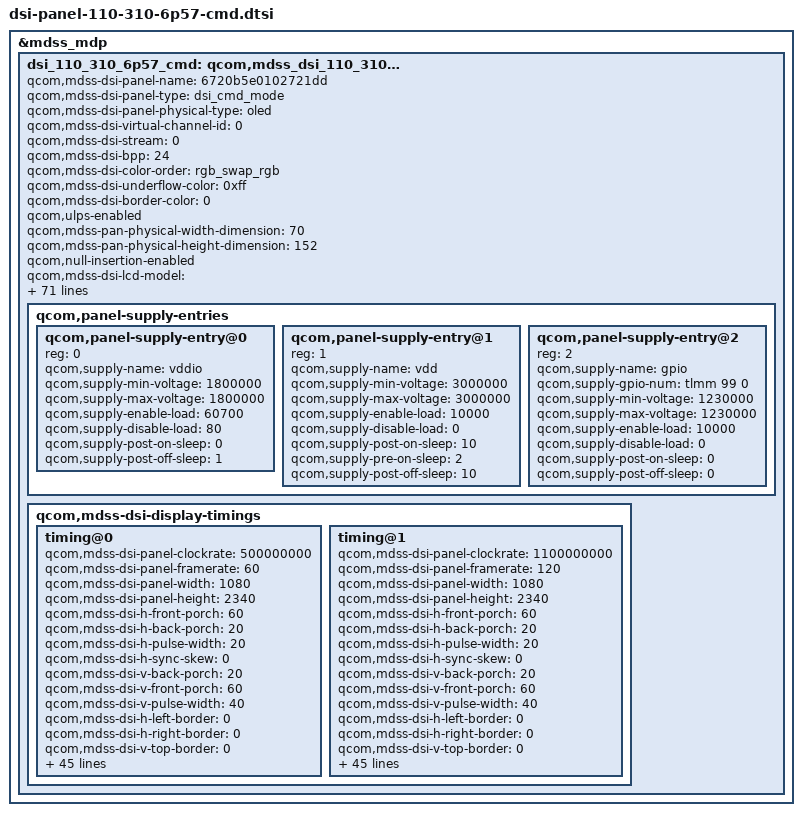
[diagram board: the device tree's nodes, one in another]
&mdss_mdp {
	dsi_110_310_6p57_cmd: qcom,mdss_dsi_110_310_6p57_cmd {
		qcom,mdss-dsi-panel-name = "6720b5e0102721dd";
		qcom,mdss-dsi-panel-type = "dsi_cmd_mode";
		qcom,mdss-dsi-panel-physical-type = "oled";
		qcom,mdss-dsi-virtual-channel-id = <0>;
		qcom,mdss-dsi-stream = <0>;
		qcom,mdss-dsi-bpp = <24>;
		qcom,mdss-dsi-color-order = "rgb_swap_rgb";
		qcom,mdss-dsi-underflow-color = <0xff>;
		qcom,mdss-dsi-border-color = <0>;
		qcom,ulps-enabled;
		qcom,mdss-pan-physical-width-dimension = <70>;
		qcom,mdss-pan-physical-height-dimension = <152>;
		qcom,null-insertion-enabled;
		qcom,mdss-dsi-lcd-model = "110_310 6p57 1080 x 2340";
		qcom,bl-dsc-cmd-state = "dsi_lp_mode";
		qcom,mdss-dsi-mdp-idle-ctrl-en;
		qcom,mdss-dsi-mdp-idle-ctrl-len = <0x18>;

		/* mipi dsi setting */
		qcom,dsi-ctrl-num = <0>;
		qcom,dsi-phy-num = <0>;
		qcom,dsi-sec-ctrl-num = <1>;
		qcom,dsi-sec-phy-num = <1>;
		qcom,mdss-dsi-traffic-mode = "non_burst_sync_event";
		qcom,mdss-dsi-lane-map = "lane_map_0123";
		qcom,mdss-dsi-bllp-eof-power-mode;
		qcom,mdss-dsi-bllp-power-mode;
		qcom,mdss-dsi-lane-0-state;
		qcom,mdss-dsi-lane-1-state;
		qcom,mdss-dsi-lane-2-state;
		qcom,mdss-dsi-lane-3-state;
		qcom,mdss-dsi-dma-trigger = "trigger_sw";
		qcom,mdss-dsi-mdp-trigger = "none";
		qcom,dsi-select-clocks = "mux_byte_clk0", "mux_pixel_clk0";
		qcom,dsi-select-sec-clocks = "mux_byte_clk1", "mux_pixel_clk1";

		/* TE setting */
		qcom,mdss-dsi-te-pin-select = <1>;
		qcom,mdss-dsi-wr-mem-start = <0x2c>;
		qcom,mdss-dsi-wr-mem-continue = <0x3c>;
		qcom,mdss-dsi-te-dcs-command = <1>;
		qcom,mdss-dsi-te-check-enable;
		qcom,mdss-dsi-te-using-te-pin;

		/* Skip send aod cmd to ic when already at aod scenes */
		qcom,mdss-dsi-skip-send-aod-enable;

		/* hdr setting */
		qcom,mdss-dsi-panel-hdr-enabled;
		qcom,mdss-dsi-panel-hdr-color-primaries = <14500 15500 32000
			17000 15500 30000 8000 3000>;
		qcom,mdss-dsi-panel-peak-brightness = <4200000>;
		qcom,mdss-dsi-panel-blackness-level = <3230>;

		/* hbm enable */
		qcom,mdss-dsi-panel-hbm-enabled;
		/* hbm delay threshold */
		qcom,mdss-dsi-hbm-left-delaythr = <500>;
		qcom,mdss-dsi-hbm-right-delaythr = <3000>;
		qcom,mdss-dsi-masklayer-delay-time = <1>;

		/* four byte bl */
		qcom,mdss-dsi-bl-four-byte-bl-enabled;

		/* gpio setting */
		qcom,dsi-panel-gpio-address = <0x0F100000 0x1000>;
		qcom,dsi-panel-gpio-pins = <44 99>;
		qcom,dsi-panel-gpio-names = "reset-gpio", "vdd-gpio";

		/* esd check setting */
		qcom,mdss-dsi-panel-status-check-mode = "reg_read";
		qcom,mdss-dsi-panel-status-command = [06 01 00 01 00 00 01 0a];
		qcom,mdss-dsi-panel-status-command-state = "dsi_lp_mode";
		qcom,mdss-dsi-panel-status-value = <0x1c>;
		qcom,mdss-dsi-panel-status-read-length = <1>;
		qcom,esd-check-enabled;

		/* check reg */
		qcom,mdss-dsi-panel-lcd-check-reg-enabled;
		qcom,mdss-dsi-panel-lcd-check-reg-expect_vals = <0x1c>;

		/* oem info */
		qcom,mdss-dsi-panel-oem-info-enabled;
		qcom,mdss-dsi-panel-oem-2d-barcode-enabled;
		qcom,mdss-dsi-panel-oem-sn-enabled;

		/* backlight setting */
		qcom,mdss-dsi-bl-pmic-control-type = "bl_ctrl_dcs";
		qcom,mdss-dsi-bl-min-level = <9>;
		qcom,mdss-dsi-bl-max-level = <4095>;
		qcom,mdss-brightness-max-level = <4095>;
		qcom,mdss-dsi-bl-inverted-dbv;
		qcom,mdss-dsi-bl-max-nit = <1000>;

		/* dfps setting */
		qcom,dsi-fps-list = <60 120>;

		/* power on/off timing setting */
		qcom,platform-reset-gpio = <&tlmm 44 0>;
		qcom,mdss-dsi-reset-sequence = <1 1>, <0 1>, <1 10>;
		qcom,mdss-dsi-reset-pre-off-sleep = <9>;
		qcom,mdss-dsi-reset-after-off-sleep = <1>;
		qcom,panel-supply-entries {
			qcom,panel-supply-entry@0 {
				reg = <0>;
				qcom,supply-name = "vddio";
				qcom,supply-min-voltage = <1800000>;
				qcom,supply-max-voltage = <1800000>;
				qcom,supply-enable-load = <60700>;
				qcom,supply-disable-load = <80>;
				qcom,supply-post-on-sleep = <0>;
				qcom,supply-post-off-sleep = <1>;
			};
			qcom,panel-supply-entry@1 {
				reg = <1>;
				qcom,supply-name = "vdd";
				qcom,supply-min-voltage = <3000000>;
				qcom,supply-max-voltage = <3000000>;
				qcom,supply-enable-load = <10000>;
				qcom,supply-disable-load = <0>;
				qcom,supply-post-on-sleep = <10>;
				qcom,supply-pre-on-sleep = <2>;
				qcom,supply-post-off-sleep = <10>;
			};
			qcom,panel-supply-entry@2 {
				reg = <2>;
				qcom,supply-name = "gpio";
				qcom,supply-gpio-num = <&tlmm 99 0>;
				qcom,supply-min-voltage = <1230000>;
				qcom,supply-max-voltage = <1230000>;
				qcom,supply-enable-load = <10000>;
				qcom,supply-disable-load = <0>;
				qcom,supply-post-on-sleep = <0>;
				qcom,supply-post-off-sleep = <0>;
			};
		};
		/* display timing0 */
		qcom,mdss-dsi-display-timings {
			timing@0 {
				qcom,mdss-dsi-panel-clockrate = <500000000>;
				qcom,mdss-dsi-panel-framerate = <60>;
				qcom,mdss-dsi-panel-width = <1080>;
				qcom,mdss-dsi-panel-height = <2340>;
				qcom,mdss-dsi-h-front-porch = <60>;
				qcom,mdss-dsi-h-back-porch = <20>;
				qcom,mdss-dsi-h-pulse-width = <20>;
				qcom,mdss-dsi-h-sync-skew = <0>;
				qcom,mdss-dsi-v-back-porch = <20>;
				qcom,mdss-dsi-v-front-porch = <60>;
				qcom,mdss-dsi-v-pulse-width = <40>;
				qcom,mdss-dsi-h-left-border = <0>;
				qcom,mdss-dsi-h-right-border = <0>;
				qcom,mdss-dsi-v-top-border = <0>;
				qcom,mdss-dsi-v-bottom-border = <0>;
				qcom,mdss-dsi-panel-jitter = <0x4 0x1>;

				qcom,mdss-dsi-on-command = [
					39 01 00 00 00 00 02 B0 A1
					39 01 00 00 00 00 05 2A 00 00 04 37
					39 01 00 00 00 00 05 2B 00 00 09 23
					15 01 00 00 00 00 02 B6 01
					39 01 00 00 00 00 06 C1 81 08 60 30 4F
					39 01 00 00 00 00 10 CA 00 59 F3 0C 01 03 20 64 04 29 00 50 00 01 00
					39 01 00 00 00 00 26 B3 54 54 00 0C 0F 3B 3C 54 54 09 4C 0F 3C 3C 54 54 03 2A 0F 5A 5A 54 54 00 0C 0F 78 78 00 0C 0F 1E 0A 00 0F 10 78
					39 01 00 00 00 00 02 B0 A6
					39 01 00 00 00 00 0B FB 00 09 00 FF FF 47 05 00 00 00
					15 01 00 00 00 00 02 B0 A6
					15 01 00 00 00 00 02 F7 AC
					15 01 00 00 00 00 02 B0 A2
					39 01 00 00 00 00 5f B3 00 00 2C 66 07 32 00 10 87 32 88 00 00 00 06 00 00 10 00 00 0F 00 00 00 00 00 00 00 00 00 00 00 00 00 00 00 00 00 00 00 11 60 75 11 60 75 11 60 75 00 00 00 00 00 00 00 00 00 00 A0 2C 00 54 60 00 80 34 00 00 00 00 00 00 00 00 00 00 00 00 00 00 00 00 00 00 00 00 00 10 00 00 00 10 08
					39 01 00 00 00 00 62 B4 26 C7 12 00 10 83 10 88 85 85 00 06 00 00 01 00 00 00 00 00 00 00 00 00 00 00 00 00 00 00 00 00 00 00 00 00 00 00 00 00 00 00 00 00 00 00 00 00 00 00 00 00 00 00 00 00 00 00 00 00 00 00 00 00 00 00 00 00 00 00 00 00 00 00 78 80 00 78 80 00 78 80 00 00 00 00 00 00 00 00 00 20 20 00 00 20 20
					39 01 00 00 00 00 12 B7 10 FF FF 00 00 00 00 00 00 00 00 00 00 00 00 01 02
					15 01 00 00 00 00 02 BB 28
					39 01 00 00 00 00 02 B0 CA
					39 01 00 00 00 00 03 3D 80 01
					39 01 00 00 00 00 03 53 00 00
					39 01 00 00 00 00 13 55 08 00 00 00 00 00 10 00 10 00 10 00 72 D0 1C 70 D0 E1
					05 01 00 00 78 00 01 11
					15 01 00 00 00 00 02 57 01
					05 01 00 00 00 00 01 35
					05 01 00 00 14 00 01 29
					39 01 00 00 00 00 02 B0 A1
				];

				qcom,mdss-dsi-off-command = [
					05 01 00 00 0A 00 01 28
					05 01 00 00 0A 00 01 13
					05 01 00 00 50 00 01 10
				];

				qcom,mdss-dsi-fp-hbm-enable-commands = [
					39 01 00 00 00 00 20 C1 81 08 60 30 4F CF 4F 36 4E 00 2F 02 00 00 0E 0E 01 CF CF CF 00 00 00 0E 0E 0E 01 00 95 00 40
					39 01 00 00 00 00 05 51 0F FF 00 00
				];

				qcom,mdss-dsi-fp-hbm-disable-commands = [
					39 01 00 00 00 00 20 C1 81 08 60 30 4F CF 4F 36 4E 00 2F 02 00 00 0E 0E 01 CF CF CF 00 00 00 0E 0E 0E 01 00 9F 00 40
				];

				qcom,mdss-dsi-timing-switch-command = [
					15 01 00 00 09 00 02 57 01
				];

				qcom,mdss-dsi-lp1-command = [
					15 01 00 00 00 00 02 57 01
					05 01 00 00 14 00 01 12
					05 01 00 00 00 00 01 28
				];

				qcom,mdss-dsi-nolp-command = [
					39 01 00 00 00 00 05 51 00 00 00 00
					05 01 00 00 00 00 01 13
					05 01 00 00 00 00 01 29
				];

				qcom,mdss-dsi-alpm-low-light-commands = [
					39 01 00 00 00 00 05 51 07 5f 00 00
					05 01 00 00 00 00 01 29
				];

				qcom,mdss-dsi-alpm-middle-light-commands = [
					39 01 00 00 00 00 05 51 0B FE 00 00
					05 01 00 00 00 00 01 29
				];

				qcom,mdss-dsi-alpm-high-light-commands = [
					39 01 00 00 00 00 05 51 0E FF 00 00
					05 01 00 00 00 00 01 29
				];

				qcom,mdss-dsi-panel-lcd-check-reg-commands = [
					06 01 00 01 00 00 01 0a
				];

				qcom,mdss-dsi-oeminfo-read-commands = [
					15 01 00 00 00 00 02 B0 A1
					05 01 00 01 00 00 01 18
					06 01 00 01 00 00 15 A9 00 00 00 00 00 00 00 00 00 00 00 00 00 00 00 00 00 00 00 00
				];

				qcom,mdss-dsi-on-command-state = "dsi_lp_mode";
				qcom,mdss-dsi-off-command-state = "dsi_hs_mode";
				qcom,mdss-dsi-panel-lcd-check-reg-commands-state =
					"dsi_lp_mode";
				qcom,mdss-dsi-oeminfo-read-commands-state =
					"dsi_lp_mode";

				qcom,mdss-dsi-h-sync-pulse = <0>;
				qcom,compression-mode = "dsc";
				qcom,mdss-dsc-version = <0x12>;
				qcom,mdss-dsc-slice-height = <60>;
				qcom,mdss-dsc-slice-width = <540>;
				qcom,mdss-dsc-slice-per-pkt = <2>;
				qcom,mdss-dsc-bit-per-component = <8>;
				qcom,mdss-dsc-bit-per-pixel = <8>;
				qcom,mdss-dsc-block-prediction-enable;
				qcom,mdss-dsi-panel-phy-timings = [00 11 03 04 12 1e 04
					04 04 03 02 04 0e 09];
				qcom,display-topology = <1 1 1>;
				qcom,default-topology-index = <0>;
			};
			timing@1 {
				qcom,mdss-dsi-panel-clockrate = <1100000000>;
				qcom,mdss-dsi-panel-framerate = <120>;
				qcom,mdss-dsi-panel-width = <1080>;
				qcom,mdss-dsi-panel-height = <2340>;
				qcom,mdss-dsi-h-front-porch = <60>;
				qcom,mdss-dsi-h-back-porch = <20>;
				qcom,mdss-dsi-h-pulse-width = <20>;
				qcom,mdss-dsi-h-sync-skew = <0>;
				qcom,mdss-dsi-v-back-porch = <20>;
				qcom,mdss-dsi-v-front-porch = <60>;
				qcom,mdss-dsi-v-pulse-width = <40>;
				qcom,mdss-dsi-h-left-border = <0>;
				qcom,mdss-dsi-h-right-border = <0>;
				qcom,mdss-dsi-v-top-border = <0>;
				qcom,mdss-dsi-v-bottom-border = <0>;
				qcom,mdss-dsi-panel-jitter = <0x4 0x1>;

				qcom,mdss-dsi-on-command = [
					39 01 00 00 00 00 02 B0 A1
					39 01 00 00 00 00 05 2A 00 00 04 37
					39 01 00 00 00 00 05 2B 00 00 09 23
					15 01 00 00 00 00 02 B6 01
					39 01 00 00 00 00 06 C1 81 08 60 30 4F
					39 01 00 00 00 00 10 CA 00 59 F3 0C 01 03 20 64 04 29 00 50 00 01 00
					39 01 00 00 00 00 26 B3 54 54 00 0C 0F 3B 3C 54 54 09 4C 0F 3C 3C 54 54 03 2A 0F 5A 5A 54 54 00 0C 0F 78 78 00 0C 0F 1E 0A 00 0F 10 78
					39 01 00 00 00 00 02 B0 A6
					39 01 00 00 00 00 0B FB 00 09 00 FF FF 47 05 00 00 00
					15 01 00 00 00 00 02 B0 A6
					15 01 00 00 00 00 02 F7 AC
					15 01 00 00 00 00 02 B0 A2
					39 01 00 00 00 00 5f B3 00 00 2C 66 07 32 00 10 87 32 88 00 00 00 06 00 00 10 00 00 0F 00 00 00 00 00 00 00 00 00 00 00 00 00 00 00 00 00 00 00 11 60 75 11 60 75 11 60 75 00 00 00 00 00 00 00 00 00 00 A0 2C 00 54 60 00 80 34 00 00 00 00 00 00 00 00 00 00 00 00 00 00 00 00 00 00 00 00 00 10 00 00 00 10 08
					39 01 00 00 00 00 62 B4 26 C7 12 00 10 83 10 88 85 85 00 06 00 00 01 00 00 00 00 00 00 00 00 00 00 00 00 00 00 00 00 00 00 00 00 00 00 00 00 00 00 00 00 00 00 00 00 00 00 00 00 00 00 00 00 00 00 00 00 00 00 00 00 00 00 00 00 00 00 00 00 00 00 00 78 80 00 78 80 00 78 80 00 00 00 00 00 00 00 00 00 20 20 00 00 20 20
					39 01 00 00 00 00 12 B7 10 FF FF 00 00 00 00 00 00 00 00 00 00 00 00 01 02
					15 01 00 00 00 00 02 BB 28
					39 01 00 00 00 00 02 B0 CA
					39 01 00 00 00 00 03 3D 80 01
					39 01 00 00 00 00 03 53 00 00
					39 01 00 00 00 00 13 55 08 00 00 00 00 00 10 00 10 00 10 00 72 D0 1C 70 D0 E1
					05 01 00 00 78 00 01 11
					15 01 00 00 00 00 02 57 03
					05 01 00 00 00 00 01 35
					05 01 00 00 14 00 01 29
					39 01 00 00 00 00 02 B0 A1
				];

				qcom,mdss-dsi-off-command = [
					05 01 00 00 0A 00 01 28
					05 01 00 00 0A 00 01 13
					05 01 00 00 50 00 01 10
				];

				qcom,mdss-dsi-fp-hbm-enable-commands = [
					39 01 00 00 00 00 20 C1 81 08 60 30 4F CF 4F 36 4E 00 2F 02 00 00 0E 0E 01 CF CF CF 00 00 00 0E 0E 0E 01 00 95 00 40
					39 01 00 00 00 00 05 51 0F FF 00 00
				];

				qcom,mdss-dsi-fp-hbm-disable-commands = [
					39 01 00 00 00 00 20 C1 81 08 60 30 4F CF 4F 36 4E 00 2F 02 00 00 0E 0E 01 CF CF CF 00 00 00 0E 0E 0E 01 00 9F 00 40
				];

				qcom,mdss-dsi-timing-switch-command = [
					15 01 00 00 11 00 02 57 03

				];

				qcom,mdss-dsi-lp1-command = [
					15 01 00 00 00 00 02 57 03
					05 01 00 00 14 00 01 12
					05 01 00 00 00 00 01 28
				];

				qcom,mdss-dsi-nolp-command = [
					39 01 00 00 00 00 05 51 00 00 00 00
					05 01 00 00 00 00 01 13
					05 01 00 00 00 00 01 29
				];

				qcom,mdss-dsi-alpm-low-light-commands = [
					39 01 00 00 00 00 05 51 07 5F 00 00
					05 01 00 00 00 00 01 29
				];

				qcom,mdss-dsi-alpm-middle-light-commands = [
					39 01 00 00 00 00 05 51 0B FE 00 00
					05 01 00 00 00 00 01 29
				];

				qcom,mdss-dsi-alpm-high-light-commands = [
					39 01 00 00 00 00 05 51 0E FF 00 00
					05 01 00 00 00 00 01 29
				];

				qcom,mdss-dsi-panel-lcd-check-reg-commands = [
					06 01 00 01 00 00 01 0a
				];

				qcom,mdss-dsi-oeminfo-read-commands = [
					15 01 00 00 00 00 02 B0 A1
					05 01 00 01 00 00 01 18
					06 01 00 01 00 00 15 A9 00 00 00 00 00 00 00 00 00 00 00 00 00 00 00 00 00 00 00 00
				];

				qcom,mdss-dsi-on-command-state = "dsi_lp_mode";
				qcom,mdss-dsi-off-command-state = "dsi_hs_mode";
				qcom,mdss-dsi-panel-lcd-check-reg-commands-state =
					"dsi_lp_mode";
				qcom,mdss-dsi-oeminfo-read-commands-state =
					"dsi_lp_mode";

				qcom,mdss-dsi-h-sync-pulse = <0>;
				qcom,compression-mode = "dsc";
				qcom,mdss-dsc-version = <0x12>;
				qcom,mdss-dsc-slice-height = <60>;
				qcom,mdss-dsc-slice-width = <540>;
				qcom,mdss-dsc-slice-per-pkt = <2>;
				qcom,mdss-dsc-bit-per-component = <8>;
				qcom,mdss-dsc-bit-per-pixel = <8>;
				qcom,mdss-dsc-block-prediction-enable;
				qcom,mdss-dsi-panel-phy-timings = [00 1c 07 07 17 16 07
					07 07 08 02 04 18 0c];
				qcom,display-topology = <1 1 1>;
				qcom,default-topology-index = <0>;
			};
		};
	};
};
